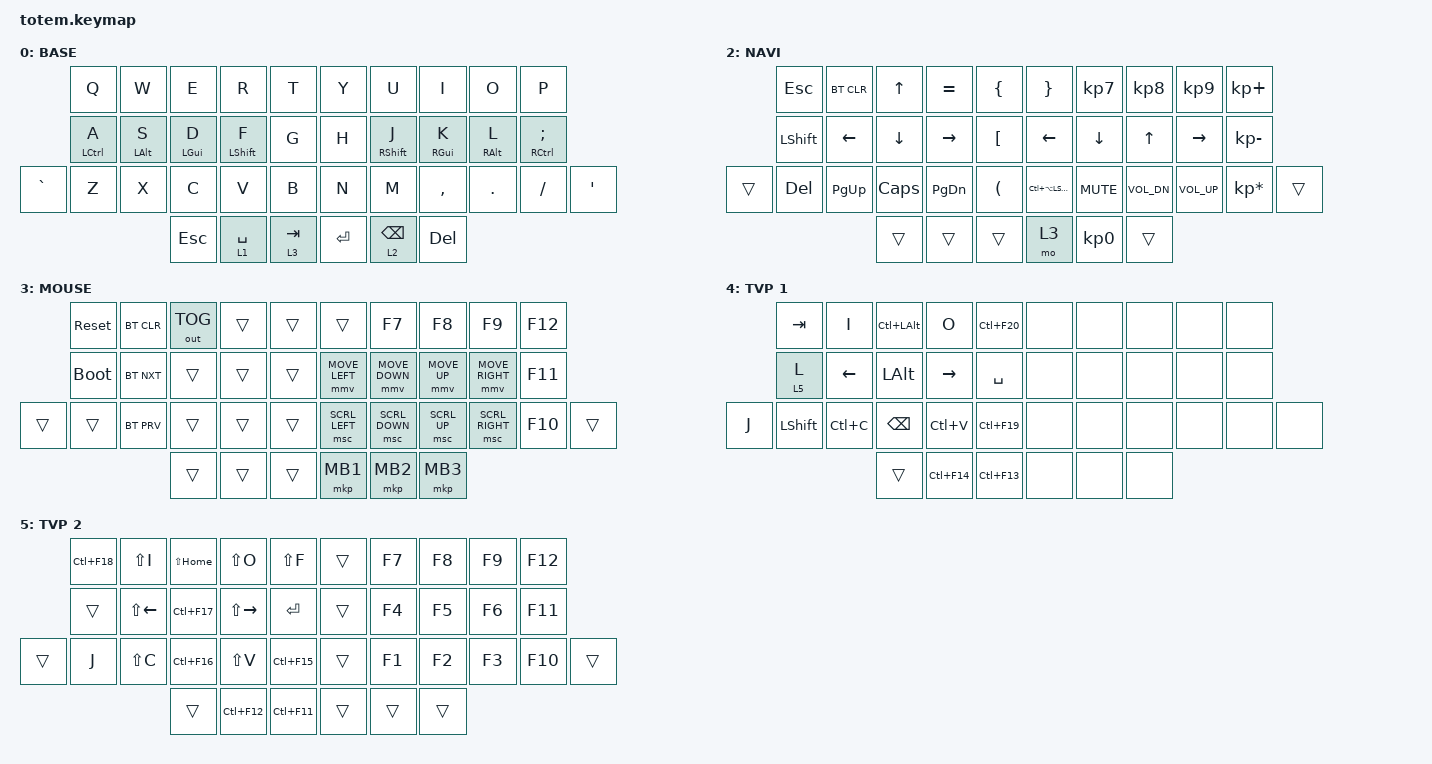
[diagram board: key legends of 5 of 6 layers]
#include <behaviors.dtsi>
#include <dt-bindings/zmk/bt.h>
#include <dt-bindings/zmk/keys.h>
#include <dt-bindings/zmk/outputs.h>
#include <dt-bindings/zmk/pointing.h>

#define BASE 0
#define NAV  1
#define SYM  2
#define MOUSE 3
#define TVP1 4
#define TVP2 5

&mt {
    retro-tap;
    quick-tap-ms = <100>;
    global-quick-tap;
    flavor = "tap-preferred";
    tapping-term-ms = <200>;
};

/ {
    combos {
        compatible = "zmk,combos";

        combo_esc {
            timeout-ms = <50>;
            key-positions = <0 1>;
            bindings = <&kp ESC>;
        };

        combo_tvp {
            timeout-ms = <100>;
            key-positions = <11 12 13>;
            bindings = <&tog 4>;
        };
    };

    keymap {
        compatible = "zmk,keymap";

        base_layer {
            label = "BASE";
            bindings = <
           &kp Q        &kp W       &kp E       &kp R        &kp T        &kp Y    &kp U        &kp I       &kp O       &kp P
           &mt LCTRL A  &mt LALT S  &mt LGUI D  &mt LSHFT F  &kp G        &kp H    &mt RSHFT J  &mt RGUI K  &mt RALT L  &mt RCTRL SEMI
&kp GRAVE  &kp Z        &kp X       &kp C       &kp V        &kp B        &kp N    &kp M        &kp COMMA   &kp DOT     &kp FSLH        &kp SQT
                                    &kp ESC     &lt 1 SPACE  &lt 3 TAB    &kp RET  &lt 2 BSPC   &kp DEL
            >;
        };

        sim_layer {
            label = "SYM";
            bindings = <
        &kp EXCL      &kp AT        &kp HASH      &kp DLLR      &kp PRCNT    &kp CARET  &kp AMPS   &kp ASTRK      &kp LEFT_PARENTHESIS  &kp RIGHT_PARENTHESIS
        &kp NUMBER_1  &kp NUMBER_2  &kp NUMBER_3  &kp NUMBER_4  &kp N5       &kp EQUAL  &kp MINUS  &kp PIPE       &kp LEFT_BRACE        &kp RIGHT_BRACE
&trans  &kp NUMBER_6  &kp N7        &kp N8        &kp N9        &kp N0       &kp PLUS   &kp UNDER  &kp BACKSLASH  &kp LEFT_BRACKET      &kp RIGHT_BRACKET      &trans
            >;
        };

        nav_layer {
            label = "NAVI";
            bindings = <
        &kp ESC    &bt BT_CLR  &kp UP    &kp EQUAL  &kp LBRC    &kp RBRC           &kp KP_N7   &kp KP_N8     &kp KP_N9        &kp KP_PLUS
        &kp LSHFT  &kp LEFT    &kp DOWN  &kp RIGHT  &kp LBKT    &kp LEFT           &kp DOWN    &kp UP_ARROW  &kp RIGHT        &kp KP_MINUS
&trans  &kp DEL    &kp PG_UP   &kp CAPS  &kp PG_DN  &kp LPAR    &kp LC(LA(LSHFT))  &kp K_MUTE  &kp C_VOL_DN  &kp C_VOLUME_UP  &kp KP_MULTIPLY  &trans
                               &trans    &trans     &trans      &mo 3     &kp KP_N0   &trans
            >;
        };

        mouse_layer {
            label = "MOUSE";
            bindings = <
        &sys_reset   &bt BT_CLR  &out OUT_TOG  &trans  &trans    &trans          &kp F7          &kp F8        &kp F9           &kp F12
        &bootloader  &bt BT_NXT  &trans        &trans  &trans    &mmv MOVE_LEFT  &mmv MOVE_DOWN  &mmv MOVE_UP  &mmv MOVE_RIGHT  &kp F11
&trans  &trans       &bt BT_PRV  &trans        &trans  &trans    &msc SCRL_LEFT  &msc SCRL_DOWN  &msc SCRL_UP  &msc SCRL_RIGHT  &kp F10  &trans
                                 &trans        &trans  &trans    &mkp MB1        &mkp MB2        &mkp MB3
            >;
        };

        tvp1_layer {
            label = "TVP 1";
            bindings = <
       &kp TAB    &kp I      &kp LC(LALT)  &kp O        &kp LC(F20)    &none  &none  &none  &none  &none
       &lt 5 L    &kp LEFT   &kp LALT      &kp RIGHT    &kp SPACE      &none  &none  &none  &none  &none
&kp J  &kp LSHFT  &kp LC(C)  &kp BSPC      &kp LC(V)    &kp LC(F19)    &none  &none  &none  &none  &none  &none
                             &trans        &kp LC(F14)  &kp LC(F13)    &none  &none  &none
            >;
        };

        tvp2_layer {
            label = "TVP 2";
            bindings = <
        &kp LC(F18)  &kp LS(I)     &kp LS(HOME)  &kp LS(O)      &kp LS(F)      &trans  &kp F7  &kp F8  &kp F9  &kp F12
        &trans       &kp LS(LEFT)  &kp LC(F17)   &kp LS(RIGHT)  &kp RET        &trans  &kp F4  &kp F5  &kp F6  &kp F11
&trans  &kp J        &kp LS(C)     &kp LC(F16)   &kp LS(V)      &kp LC(F15)    &trans  &kp F1  &kp F2  &kp F3  &kp F10  &trans
                                   &trans        &kp LC(F12)    &kp LC(F11)    &trans  &trans  &trans
            >;
        };
    };
};
